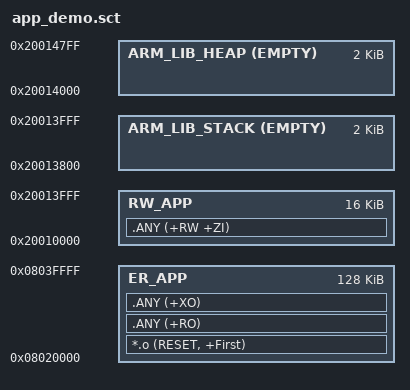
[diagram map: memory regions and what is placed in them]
; *************************************************************
; *** SVCrtOS App SDK ??????��??? Scatter File           ***
; *** ?????????????????? ROM ???? 0x08020000             ***
; *** RAM ??? 0x20010000 ?? 16KB?????????????              ***
; *************************************************************

LR_APP 0x08020000 0x00020000  {        ; ??? ROM ???? 128KB
  ER_APP 0x08020000 0x00020000  {
   *.o (RESET, +First)                 ; APPSTART ???????????????
   .ANY (+RO)
   .ANY (+XO)
  }
  RW_APP 0x20010000 0x00004000  {      ; ??? RAM ???? 16KB
   .ANY (+RW +ZI)
  }
  ARM_LIB_STACK 0x20014000 EMPTY -0x800 {   ; ???? 2KB
  }
  ARM_LIB_HEAP  0x20014000 EMPTY 0x800 {    ; ???? 2KB
  }
}
